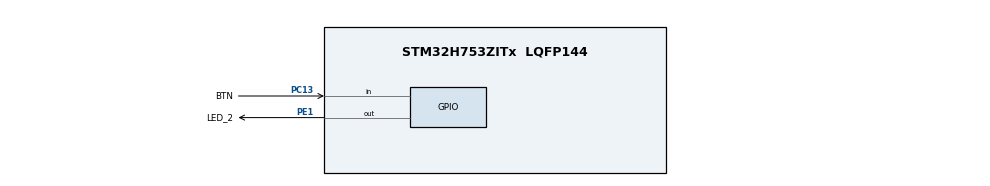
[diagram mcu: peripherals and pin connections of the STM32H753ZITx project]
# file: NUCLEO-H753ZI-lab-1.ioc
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Mcu.Family=STM32H7
Mcu.Name=STM32H753ZITx
Mcu.Package=LQFP144
NVIC.PriorityGroup=NVIC_PRIORITYGROUP_4
PA13\ (JTMS/SWDIO).Mode=Trace_Asynchronous_SW
PA13\ (JTMS/SWDIO).Signal=DEBUG_JTMS-SWDIO
PA14\ (JTCK/SWCLK).Mode=Trace_Asynchronous_SW
PA14\ (JTCK/SWCLK).Signal=DEBUG_JTCK-SWCLK
PB3\ (JTDO/TRACESWO).Mode=Trace_Asynchronous_SW
PB3\ (JTDO/TRACESWO).Signal=DEBUG_JTDO-SWO
PC13.GPIO_Label=BTN
PC13.Signal=GPIO_Input
PE1.GPIO_Label=LED_2
PE1.Signal=GPIO_Output
PH0-OSC_IN\ (PH0).Mode=HSE-External-Oscillator
PH0-OSC_IN\ (PH0).Signal=RCC_OSC_IN
PH1-OSC_OUT\ (PH1).Mode=HSE-External-Oscillator
PH1-OSC_OUT\ (PH1).Signal=RCC_OSC_OUT
ProjectManager.HeapSize=0x200
ProjectManager.StackSize=0x400
ProjectManager.TargetToolchain=STM32CubeIDE
RCC.ADCFreq_Value=16125000
RCC.APB1Freq_Value=120000000
RCC.APB2Freq_Value=120000000
RCC.APB3Freq_Value=120000000
RCC.APB4Freq_Value=120000000
RCC.CortexFreq_Value=480000000
RCC.D1PPRE=RCC_APB3_DIV2
RCC.D2PPRE1=RCC_APB1_DIV2
RCC.D2PPRE2=RCC_APB2_DIV2
RCC.D3PPRE=RCC_APB4_DIV2
RCC.DIVM1=1
RCC.DIVN1=120
RCC.HCLKFreq_Value=240000000
RCC.HPRE=RCC_HCLK_DIV2
RCC.HSE_VALUE=8000000
RCC.PLL2FRACN=0
RCC.PLL3FRACN=0
RCC.PLLFRACN=0
RCC.PLLSourceVirtual=RCC_PLLSOURCE_HSE
RCC.SYSCLKFreq_VALUE=480000000
RCC.SYSCLKSource=RCC_SYSCLKSOURCE_PLLCLK
RCC.USBFreq_Value=480000000
VP_MEMORYMAP_VS_MEMORYMAP.Mode=CurAppReg
board=custom

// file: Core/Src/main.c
/* USER CODE BEGIN Header */
/**
 ******************************************************************************
 * @file           : main.c
 * @brief          : Main program body
 ******************************************************************************
 * @attention
 *
 * Copyright (c) 2025 STMicroelectronics.
 * All rights reserved.
 *
 * This software is licensed under terms that can be found in the LICENSE file
 * in the root directory of this software component.
 * If no LICENSE file comes with this software, it is provided AS-IS.
 *
 ******************************************************************************
 */
/* USER CODE END Header */
#include "main.h"
#include "gpio.h"

/* USER CODE BEGIN PTD */

typedef enum {
	Init, Step1, Step2, Step3, Step4, Step5, Step6, Stop
} State;

typedef struct {
	uint32_t HalfPeriod;
	uint32_t TogglesNum;
	uint32_t MaxTogglesNum;

} StateContext;

/* USER CODE END PTD */

/* USER CODE BEGIN PM */
#define DEBOUNCE_DELAY_MS 20

#define SHORT_FQ 3
#define MEDIUM_FQ 5
#define LONG_FQ 10

#define SHORT_DELAY_SEC 1
#define MEDIUM_DELAY_SEC 1
#define LONG_DELAY_SEC 1

#define HZ_TO_MILIS_HALF_PERIOD(hz) (1000 / 2 * 1 / (hz))

#define TOGGLES_NUM(fq, delay_sec) (2 * (fq) * (delay_sec))

/* USER CODE END PM */

/* USER CODE BEGIN PV */
State CurrentState = Init;

StateContext StateContexts[] = { { 0, 0, 0 },
		{ HZ_TO_MILIS_HALF_PERIOD(SHORT_FQ), 0, TOGGLES_NUM(SHORT_FQ, SHORT_DELAY_SEC) },
		{ HZ_TO_MILIS_HALF_PERIOD(MEDIUM_FQ), 0, TOGGLES_NUM(MEDIUM_FQ, MEDIUM_DELAY_SEC) },
		{ HZ_TO_MILIS_HALF_PERIOD(LONG_FQ), 0, TOGGLES_NUM(LONG_FQ, LONG_DELAY_SEC) },
		{ HZ_TO_MILIS_HALF_PERIOD(LONG_FQ), 0, TOGGLES_NUM(LONG_FQ, LONG_DELAY_SEC) },
		{ HZ_TO_MILIS_HALF_PERIOD(SHORT_FQ), 0, TOGGLES_NUM(MEDIUM_FQ, MEDIUM_DELAY_SEC) },
		{ HZ_TO_MILIS_HALF_PERIOD(SHORT_FQ), 0, TOGGLES_NUM(SHORT_FQ, SHORT_DELAY_SEC) },
		{0, 0, 0} };

uint32_t LastDelayTime = 0;

/* USER CODE END PV */

void SystemClock_Config(void);

/* USER CODE BEGIN 0 */

void ToggleLED() {
	HAL_GPIO_TogglePin(LED_2_GPIO_Port, LED_2_Pin);
	LastDelayTime = HAL_GetTick();
	StateContexts[CurrentState].TogglesNum++;
}

void ResetLED() {
	HAL_GPIO_WritePin(LED_2_GPIO_Port, LED_2_Pin, GPIO_PIN_RESET);
	StateContexts[CurrentState].TogglesNum = 0;
}

void TurnOnLED() {
	HAL_GPIO_WritePin(LED_2_GPIO_Port, LED_2_Pin, GPIO_PIN_SET);
}

uint32_t GetHalfPeriod() {
	return StateContexts[CurrentState].HalfPeriod;
}

uint32_t IsMaxTogglesNum() {
	StateContext Ctx = StateContexts[CurrentState];
	return Ctx.MaxTogglesNum == Ctx.TogglesNum;
}

void GotoState(State state) {
	CurrentState = state;
	StateContexts[CurrentState].TogglesNum = 0;
}

/* USER CODE END 0 */

int main(void) {

	/* MCU Configuration--------------------------------------------------------*/

	/* Reset of all peripherals, Initializes the Flash interface and the Systick. */
	HAL_Init();

	/* Configure the system clock */
	SystemClock_Config();

	/* Initialize all configured peripherals */
	MX_GPIO_Init();
	/* USER CODE BEGIN 2 */
	uint32_t LastDebounceTime = 0;
	uint8_t BtnState = GPIO_PIN_RESET;
	uint8_t LastBtnState = GPIO_PIN_RESET;
	uint8_t BtnReading;

	ResetLED();
	/* USER CODE END 2 */

	/* Infinite loop */
	/* USER CODE BEGIN WHILE */
	while (1) {
		BtnReading = HAL_GPIO_ReadPin(BTN_GPIO_Port, BTN_Pin);
		if (BtnReading != LastBtnState) {
			LastDebounceTime = HAL_GetTick();
		}
		if ((HAL_GetTick() - LastDebounceTime) > DEBOUNCE_DELAY_MS) {
			if (BtnReading != BtnState) {
				BtnState = BtnReading;
				if (BtnState == 1) {
					LastDelayTime = HAL_GetTick();
					if (CurrentState == Init) {
						ResetLED();
						GotoState(Step1);
						ToggleLED();
					} else if (CurrentState == Stop) {
						ResetLED();
						GotoState(Step4);
						ToggleLED();
					}
				}
			}
		}
		LastBtnState = BtnReading;
		if (IsMaxTogglesNum()) {
			switch (CurrentState) {
			case Step1:
				GotoState(Step2);
				break;
			case Step2:
				GotoState(Step3);
				break;
			case Step3:
				GotoState(Stop);
				break;
			case Step4:
				GotoState(Step5);
				break;
			case Step5:
				GotoState(Step6);
				break;
			case Step6:
				GotoState(Init);
				ResetLED();
				break;
			case Stop:
				TurnOnLED();
				break;
			default:
			}
		}

		if (CurrentState > Init && CurrentState < Stop
				&& ((HAL_GetTick() - LastDelayTime) >= GetHalfPeriod())) {
			ToggleLED();
		}
		/* USER CODE END WHILE */

	}
}

void SystemClock_Config(void) {
	RCC_OscInitTypeDef RCC_OscInitStruct = { 0 };
	RCC_ClkInitTypeDef RCC_ClkInitStruct = { 0 };

	/** Supply configuration update enable
	 */
	HAL_PWREx_ConfigSupply(PWR_LDO_SUPPLY);

	/** Configure the main internal regulator output voltage
	 */
	__HAL_PWR_VOLTAGESCALING_CONFIG(PWR_REGULATOR_VOLTAGE_SCALE0);

	while (!__HAL_PWR_GET_FLAG(PWR_FLAG_VOSRDY)) {
	}

	/** Initializes the RCC Oscillators according to the specified parameters
	 * in the RCC_OscInitTypeDef structure.
	 */
	RCC_OscInitStruct.OscillatorType = RCC_OSCILLATORTYPE_HSE;
	RCC_OscInitStruct.HSEState = RCC_HSE_ON;
	RCC_OscInitStruct.PLL.PLLState = RCC_PLL_ON;
	RCC_OscInitStruct.PLL.PLLSource = RCC_PLLSOURCE_HSE;
	RCC_OscInitStruct.PLL.PLLM = 1;
	RCC_OscInitStruct.PLL.PLLN = 120;
	RCC_OscInitStruct.PLL.PLLP = 2;
	RCC_OscInitStruct.PLL.PLLQ = 2;
	RCC_OscInitStruct.PLL.PLLR = 2;
	RCC_OscInitStruct.PLL.PLLRGE = RCC_PLL1VCIRANGE_3;
	RCC_OscInitStruct.PLL.PLLVCOSEL = RCC_PLL1VCOWIDE;
	RCC_OscInitStruct.PLL.PLLFRACN = 0;
	if (HAL_RCC_OscConfig(&RCC_OscInitStruct) != HAL_OK) {
		Error_Handler();
	}

	/** Initializes the CPU, AHB and APB buses clocks
	 */
	RCC_ClkInitStruct.ClockType = RCC_CLOCKTYPE_HCLK | RCC_CLOCKTYPE_SYSCLK
			| RCC_CLOCKTYPE_PCLK1 | RCC_CLOCKTYPE_PCLK2 | RCC_CLOCKTYPE_D3PCLK1
			| RCC_CLOCKTYPE_D1PCLK1;
	RCC_ClkInitStruct.SYSCLKSource = RCC_SYSCLKSOURCE_PLLCLK;
	RCC_ClkInitStruct.SYSCLKDivider = RCC_SYSCLK_DIV1;
	RCC_ClkInitStruct.AHBCLKDivider = RCC_HCLK_DIV2;
	RCC_ClkInitStruct.APB3CLKDivider = RCC_APB3_DIV2;
	RCC_ClkInitStruct.APB1CLKDivider = RCC_APB1_DIV2;
	RCC_ClkInitStruct.APB2CLKDivider = RCC_APB2_DIV2;
	RCC_ClkInitStruct.APB4CLKDivider = RCC_APB4_DIV2;

	if (HAL_RCC_ClockConfig(&RCC_ClkInitStruct, FLASH_LATENCY_4) != HAL_OK) {
		Error_Handler();
	}
}

void Error_Handler(void) {
	__disable_irq();
	while (1) {
	}
}
